# ESP32S31_RADIO register map
Vendor: Espressif; Series: ESP32-S31; File version: 3.52
Registers are 32-bit, read-write, no defined reset value unless marked. A register's access mark holds for its fields unless they carry their own. Offsets are from the block's base; [hi:lo] are bit positions; {n}, {i} and the like mark numbered series.

## PHY_I2C_COMMAND_RAM — Official S31 reg_base.h names this aperture DR_REG_I2C_ANA_MST_MEM_BASE. The complete blob establishes its forty-five-entry command layout and the population order in phy_i2c_master_cmd_mem_init. Complete phy_i2c_check independently names ten logical banks, their block IDs, selected host and finite register-index ranges.
Base 0x2010FC00
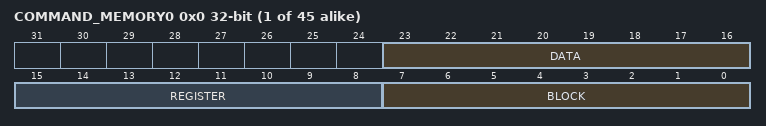
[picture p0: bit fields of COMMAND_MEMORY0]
{0x0+4i} COMMAND_MEMORY{i} (i=0..44) wo — One PHY-I2C master command-memory entry; the public header proves the containing memory aperture while the complete blob proves this word layout.
  [23:16] DATA
  [15:8] REGISTER
  [7:0] BLOCK — Logical PHY-I2C block ID. The bank host and valid half-open register-index ranges are: SAR1 host 0 [0,7), ULP host 1 [0,11), RFPLL host 1 [0,22), RFPLL_SDM host 1 [0,7), BBPLL host 0 [0,11), BBTOP host 1 [0,57), PERIF host 0 [0,13), BIAS host 1 [0,4), TXRF host 1 [1,22), DIG_REG host 0 [0,15).
    16=SAR1; 97=ULP; 98=RFPLL; 99=RFPLL_SDM; 102=BBPLL; 103=BBTOP; 105=PERIF; 106=BIAS; 107=TXRF; 109=DIG_REG

## PHY_IQ_ESTIMATOR_ORACLE — DC/IQ estimator configuration, signed result and activity registers recovered from complete S31 rev0 ROM bodies and the complete pinned phy_check_rx_sat blob leaf. Unknown electrical roles remain explicit.
Base 0x20100000
0x44C ESTIMATOR_CONFIG — Complete phy_iq_est_enable replaces bits 27:26 with encoding one before each measurement.
  [27:26] CONFIG_MODE_UNKNOWN — Two-bit field set to encoding one by phy_iq_est_enable.
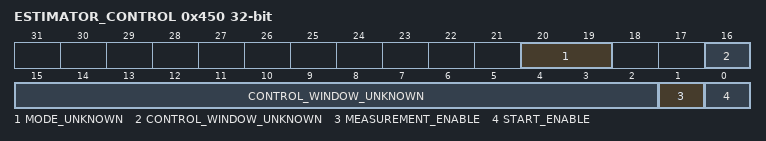
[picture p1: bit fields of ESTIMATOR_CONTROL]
0x450 ESTIMATOR_CONTROL — Complete phy_iq_est_enable publishes the caller control word and starts both measurement phases; complete phy_iq_est_disable clears them in reverse order around a one-microsecond delay.
  [20:19] MODE_UNKNOWN — Complete phy_iq_est_enable replaces the field with encoding two.
  [16:2] CONTROL_WINDOW_UNKNOWN — Fifteen-bit caller value shifted left by two.
  [1] MEASUREMENT_ENABLE
  [0] START_ENABLE
0x454 SIGNAL_POWER_SUM_I ro — Signed result consumed by complete phy_rxiq_get_mis and phy_get_rx_sig_pwr.
  [31:0] VALUE — Complete signed estimator result.
0x458 SIGNAL_POWER_DIFFERENCE_I ro — Signed result consumed by complete phy_rxiq_get_mis and phy_get_rx_sig_pwr.
  [31:0] VALUE — Complete signed estimator result.
0x45C SIGNAL_POWER_DIFFERENCE_Q ro — Signed result consumed by complete phy_rxiq_get_mis and phy_get_rx_sig_pwr.
  [31:0] VALUE — Complete signed estimator result.
0x460 SIGNAL_POWER_SUM_Q ro — Signed result consumed by complete phy_rxiq_get_mis and phy_get_rx_sig_pwr.
  [31:0] VALUE — Complete signed estimator result.
0x464 DC_I_ACCUMULATOR ro — First signed accumulator read by complete phy_dc_iq_est.
  [31:0] VALUE — Complete signed accumulator value.
0x468 DC_Q_ACCUMULATOR ro — Second signed accumulator read by complete phy_dc_iq_est.
  [31:0] VALUE — Complete signed accumulator value.
0x46C POWER_ACCUMULATOR ro — Signed power accumulator consumed by complete phy_dc_iq_est, phy_rxiq_get_mis and phy_set_rx_gain_cal_iq.
  [31:0] VALUE — Complete signed accumulator value.
0x47C ESTIMATOR_READY_STATUS ro — Complete phy_iq_est_enable tests bit 16 before leaving its readiness loop.
  [16] READY
0x8D0 ESTIMATOR_ACTIVITY_STATUS ro — Complete phy_iq_est_enable counts nonzero bits 21:20 while waiting; complete phy_check_rx_sat samples the same field exactly 100 times.
  [21:20] ACTIVITY_UNKNOWN — Nonzero is treated as IQ-estimator activity and as an RX-saturation sample.

## PHY_RX_DCO_ORACLE — RX-DCO calibration control word recovered from complete pinned S31 blob and rev0 ROM calibration bodies.
Base 0x20100000
0x434 CONTROL — Complete phy_xtal_duty_cal and RX-DCO calibration bodies save, clear and restore bits 23:22 around measurement.
  [23:22] CALIBRATION_CONTROL_UNKNOWN — Two-bit field preserved around the complete bounded RX-DCO measurement graph.
